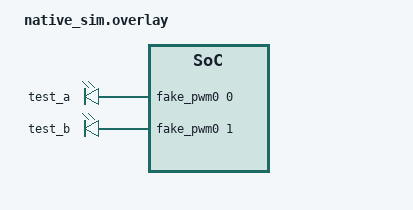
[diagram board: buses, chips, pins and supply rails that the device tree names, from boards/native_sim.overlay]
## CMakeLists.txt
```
cmake_minimum_required(VERSION 3.20.0)
include(${CMAKE_CURRENT_SOURCE_DIR}/../../unit.cmake)
zbook_unit_test(pwm)
```

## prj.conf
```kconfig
CONFIG_ZTEST=y
CONFIG_ZBOOK_PWM=y
```

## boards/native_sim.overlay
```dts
#include <zephyr/dt-bindings/pwm/pwm.h>

/ {
	fake_pwm0: fake-pwm0 {
		compatible = "zephyr,fake-pwm";
		status = "okay";
		#pwm-cells = <2>;
		frequency = <1000000000>;
	};

	zbook_pwm_channels: zbook-pwm-channels {
		compatible = "pwm-leds";

		zbook_pwm_test_a: zbook-pwm-test-a {
			label = "test_a";
			pwms = <&fake_pwm0 0 PWM_USEC(1000)>;
		};

		zbook_pwm_test_b: zbook-pwm-test-b {
			label = "test_b";
			pwms = <&fake_pwm0 1 PWM_USEC(2000)>;
		};
	};
};
```

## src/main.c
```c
#include <zephyr/ztest.h>
#include <zephyr/fff.h>
#include <zephyr/drivers/pwm/pwm_fake.h>

#include "actuators/zbook_pwm.h"

DEFINE_FFF_GLOBALS;

ZTEST_SUITE(zbook_pwm, NULL, NULL, NULL, NULL, NULL);

ZTEST(zbook_pwm, test_00_not_wired_up)
{
	struct zbook_pwm_cfg cfg = {.frequency_hz = 1000, .duty_cycle_percent = 50};

	zassert_equal(-ENODEV, zbook_pwm_init(ZBOOK_PWM_IO45));
	zassert_equal(-ENODEV, zbook_pwm_start(ZBOOK_PWM_IO45));
	zassert_equal(-ENODEV, zbook_pwm_stop(ZBOOK_PWM_IO45));
	zassert_equal(-ENODEV, zbook_pwm_set_cfg(ZBOOK_PWM_IO45, &cfg));
	zassert_equal(-ENODEV, zbook_pwm_get_cfg(ZBOOK_PWM_IO45, &cfg));

	zassert_equal(0, fake_pwm_set_cycles_fake.call_count);
}

ZTEST(zbook_pwm, test_01_not_ready_before_init)
{
	struct zbook_pwm_cfg cfg = {.frequency_hz = 1000, .duty_cycle_percent = 50};

	/* ZBOOK_PWM_IO01 exists in devicetree but zbook_pwm_init() hasn't run
	 * yet -- distinct from test_00's "not wired up" (ch == NULL) branch.
	 */
	zassert_equal(-ENODEV, zbook_pwm_start(ZBOOK_PWM_IO01));
	zassert_equal(-ENODEV, zbook_pwm_stop(ZBOOK_PWM_IO01));
	zassert_equal(-ENODEV, zbook_pwm_set_cfg(ZBOOK_PWM_IO01, &cfg));
	zassert_equal(-ENODEV, zbook_pwm_get_cfg(ZBOOK_PWM_IO01, &cfg));

	zassert_equal(0, fake_pwm_set_cycles_fake.call_count);
}

ZTEST(zbook_pwm, test_02_init_ok_seeds_default_cfg)
{
	struct zbook_pwm_cfg cfg;

	zassert_ok(zbook_pwm_init(ZBOOK_PWM_IO01));

	/* init() applies the default cfg (0% duty) once, on channel 0. */
	zassert_equal(1, fake_pwm_set_cycles_fake.call_count);
	zassert_equal(0, fake_pwm_set_cycles_fake.arg1_val);
	zassert_equal(1000000, fake_pwm_set_cycles_fake.arg2_val);
	zassert_equal(0, fake_pwm_set_cycles_fake.arg3_val);
	zassert_equal(PWM_POLARITY_NORMAL, fake_pwm_set_cycles_fake.arg4_val);

	/* Default frequency seeded from the devicetree period (1000000ns -> 1000Hz). */
	zassert_ok(zbook_pwm_get_cfg(ZBOOK_PWM_IO01, &cfg));
	zassert_equal(1000, cfg.frequency_hz);
	zassert_equal(0, cfg.duty_cycle_percent);
	zassert_equal(ZBOOK_PWM_POLARITY_NORMAL, cfg.polarity);
}

ZTEST(zbook_pwm, test_03_init_second_channel_uses_its_own_index)
{
	struct zbook_pwm_cfg cfg;

	zassert_ok(zbook_pwm_init(ZBOOK_PWM_IO39));

	zassert_equal(1, fake_pwm_set_cycles_fake.call_count);
	zassert_equal(1, fake_pwm_set_cycles_fake.arg1_val);
	zassert_equal(2000000, fake_pwm_set_cycles_fake.arg2_val);
	zassert_equal(0, fake_pwm_set_cycles_fake.arg3_val);

	zassert_ok(zbook_pwm_get_cfg(ZBOOK_PWM_IO39, &cfg));
	zassert_equal(500, cfg.frequency_hz);
	zassert_equal(0, cfg.duty_cycle_percent);
}

ZTEST(zbook_pwm, test_04_set_cfg_while_stopped_forces_zero_duty)
{
	struct zbook_pwm_cfg cfg = {
		.frequency_hz = 500,
		.duty_cycle_percent = 75,
		.polarity = ZBOOK_PWM_POLARITY_NORMAL,
	};

	zassert_ok(zbook_pwm_set_cfg(ZBOOK_PWM_IO01, &cfg));

	/* Not started yet -- duty is forced to 0 regardless of cfg. */
	zassert_equal(1, fake_pwm_set_cycles_fake.call_count);
	zassert_equal(2000000, fake_pwm_set_cycles_fake.arg2_val);
	zassert_equal(0, fake_pwm_set_cycles_fake.arg3_val);
	zassert_equal(PWM_POLARITY_NORMAL, fake_pwm_set_cycles_fake.arg4_val);
}

ZTEST(zbook_pwm, test_05_start_applies_configured_duty)
{
	zassert_ok(zbook_pwm_start(ZBOOK_PWM_IO01));

	/* Same cfg as the previous test (500Hz, 75%), now actually applied. */
	zassert_equal(1, fake_pwm_set_cycles_fake.call_count);
	zassert_equal(2000000, fake_pwm_set_cycles_fake.arg2_val);
	zassert_equal(1500000, fake_pwm_set_cycles_fake.arg3_val);
}

ZTEST(zbook_pwm, test_06_set_cfg_live_while_playing_updates_duty_and_polarity)
{
	struct zbook_pwm_cfg cfg = {
		.frequency_hz = 250,
		.duty_cycle_percent = 25,
		.polarity = ZBOOK_PWM_POLARITY_INVERTED,
	};

	zassert_ok(zbook_pwm_set_cfg(ZBOOK_PWM_IO01, &cfg));

	/* Still playing -- new duty is applied immediately, not deferred to
	 * a start() call, and the new polarity reaches pwm_set() as flags.
	 */
	zassert_equal(1, fake_pwm_set_cycles_fake.call_count);
	zassert_equal(4000000, fake_pwm_set_cycles_fake.arg2_val);
	zassert_equal(1000000, fake_pwm_set_cycles_fake.arg3_val);
	zassert_equal(PWM_POLARITY_INVERTED, fake_pwm_set_cycles_fake.arg4_val);
}

ZTEST(zbook_pwm, test_07_stop_zeroes_duty_keeps_rest_of_cfg)
{
	zassert_ok(zbook_pwm_stop(ZBOOK_PWM_IO01));

	zassert_equal(1, fake_pwm_set_cycles_fake.call_count);
	zassert_equal(4000000, fake_pwm_set_cycles_fake.arg2_val);
	zassert_equal(0, fake_pwm_set_cycles_fake.arg3_val);
	zassert_equal(PWM_POLARITY_INVERTED, fake_pwm_set_cycles_fake.arg4_val);
}

ZTEST(zbook_pwm, test_08_get_cfg_reflects_last_set_not_hardware)
{
	struct zbook_pwm_cfg cfg;

	/* Duty at the hardware is 0 right now (stopped), but get_cfg() must
	 * still report the last requested 25%, not the applied 0%.
	 */
	zassert_ok(zbook_pwm_get_cfg(ZBOOK_PWM_IO01, &cfg));
	zassert_equal(250, cfg.frequency_hz);
	zassert_equal(25, cfg.duty_cycle_percent);
	zassert_equal(ZBOOK_PWM_POLARITY_INVERTED, cfg.polarity);

	zassert_equal(0, fake_pwm_set_cycles_fake.call_count);
}

ZTEST(zbook_pwm, test_09_set_cfg_invalid_args)
{
	struct zbook_pwm_cfg zero_freq = {.frequency_hz = 0, .duty_cycle_percent = 50};
	struct zbook_pwm_cfg bad_duty = {.frequency_hz = 100, .duty_cycle_percent = 101};

	zassert_equal(-EINVAL, zbook_pwm_set_cfg(ZBOOK_PWM_IO01, NULL));
	zassert_equal(-EINVAL, zbook_pwm_set_cfg(ZBOOK_PWM_IO01, &zero_freq));
	zassert_equal(-EINVAL, zbook_pwm_set_cfg(ZBOOK_PWM_IO01, &bad_duty));

	zassert_equal(0, fake_pwm_set_cycles_fake.call_count);
}

ZTEST(zbook_pwm, test_10_get_cfg_invalid_args)
{
	zassert_equal(-EINVAL, zbook_pwm_get_cfg(ZBOOK_PWM_IO01, NULL));

	zassert_equal(0, fake_pwm_set_cycles_fake.call_count);
}

ZTEST(zbook_pwm, test_11_second_channel_independent_of_first)
{
	struct zbook_pwm_cfg cfg = {
		.frequency_hz = 100,
		.duty_cycle_percent = 50,
		.polarity = ZBOOK_PWM_POLARITY_NORMAL,
	};
	struct zbook_pwm_cfg cfg_io01;

	zassert_ok(zbook_pwm_set_cfg(ZBOOK_PWM_IO39, &cfg));
	zassert_equal(1, fake_pwm_set_cycles_fake.arg1_val);
	zassert_equal(10000000, fake_pwm_set_cycles_fake.arg2_val);
	zassert_equal(0, fake_pwm_set_cycles_fake.arg3_val);

	zassert_ok(zbook_pwm_start(ZBOOK_PWM_IO39));
	zassert_equal(1, fake_pwm_set_cycles_fake.arg1_val);
	zassert_equal(10000000, fake_pwm_set_cycles_fake.arg2_val);
	zassert_equal(5000000, fake_pwm_set_cycles_fake.arg3_val);

	/* ZBOOK_PWM_IO01 (channel 0) must be untouched by any of the
	 * ZBOOK_PWM_IO39 (channel 1) calls above.
	 */
	zassert_ok(zbook_pwm_get_cfg(ZBOOK_PWM_IO01, &cfg_io01));
	zassert_equal(250, cfg_io01.frequency_hz);
	zassert_equal(25, cfg_io01.duty_cycle_percent);
	zassert_equal(ZBOOK_PWM_POLARITY_INVERTED, cfg_io01.polarity);
}
```
